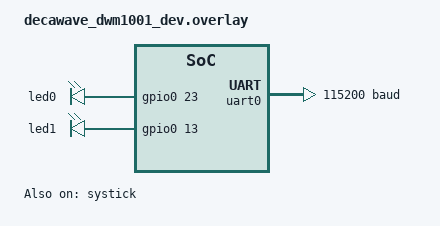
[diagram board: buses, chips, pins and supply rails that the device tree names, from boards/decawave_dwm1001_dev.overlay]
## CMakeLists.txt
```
cmake_minimum_required(VERSION 3.20.0)

find_package(Zephyr)
project(uwb_swarm_ranging)

target_sources(app PRIVATE
  # src/main.c
  src/nodes.c
  src/log.c
  src/utils.c
  src/debug-gpio.c
  src/history.c
  src/ranging-engine.c
  # src/rangings-slots.c
  src/time-synchronization.c
  src/testbeds/testbed_kiel.c
  src/testbeds/testbed_toulouse.c
  src/testbeds/testbed_drone.c
  src/testbeds/testbed_lille.c
  src/testbeds/testbed_trento_a.c
  src/testbeds/testbed_trento_b.c


  # apps/cir-evaluation.c
  # apps/ranging-with-imu.c
  # apps/cycle-slot-durations.c
  # apps/random-contention-access.c
  apps/fixed-contention-access.c
)
```

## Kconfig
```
config NUM_NODES
    int "Number of nodes"
    default 2

config GLOSSY_TX_FLOOD_START_NODE_ID
    int "Glossy TX flood start node ID"
    default 8

config DWT_MTM_OUTPUT_CIR
    bool "output channel impulse response"
    default n

config DWT_MTM_ON_DEVICE_PROCESSING
    bool "if n just output raw timestamps"
    default y

choice RANGING_OUTPUT_TARGET
    bool "output target interface"
    default RANGING_OUTPUT_RTT

config RANGING_OUTPUT_RTT
    bool "RANGING_OUTPUT_RTT"

config RANGING_OUTPUT_UART
    bool "RANGING_OUTPUT_UART"

endchoice

choice TESTBED
    bool "Testbed"
    default TESTBED_KIEL

config TESTBED_KIEL
    bool "TESTBED_KIEL"

config TESTBED_TOULOUSE
    bool "TESTBED_TOULOUSE"

config TESTBED_DRONE
    bool "TESTBED_DRONE"

config TESTBED_LILLE
    bool "TESTBED_LILLE"

config TESTBED_TRENTO_A
    bool "TESTBED_TRENTO_A"

config TESTBED_TRENTO_B
    bool "TESTBED_TRENTO_B"
endchoice


source "Kconfig.zephyr"
```

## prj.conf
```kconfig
CONFIG_LOG=y
CONFIG_LOG_DEFAULT_LEVEL=4
CONFIG_LOG_MODE_IMMEDIATE=y
CONFIG_LOG_PRINTK=y

#CONFIG_SCHED_SCALABLE=y

# CONFIG_NET_TC_THREAD_COOPERATIVE=y
CONFIG_NETWORKING=y
CONFIG_IEEE802154=y
CONFIG_IEEE802154_DW1000=y
CONFIG_NET_PKT_TIMESTAMP=y
CONFIG_IEEE802154_RAW_MODE=y
CONFIG_NEWLIB_LIBC=y
CONFIG_NEWLIB_LIBC_NANO=n

# CONFIG_NEWLIB_LIBC_FLOAT_PRINTF=y
CONFIG_CBPRINTF_FP_SUPPORT=y.

CONFIG_SERIAL=y

CONFIG_UART_ASYNC_API=y

# UART LOGGING: enable both again if log should be output through uart, not only RTT

# OPTION 1 LOG through RTT
CONFIG_UART_CONSOLE=n
CONFIG_LOG_BACKEND_UART=n
CONFIG_USE_SEGGER_RTT=y
CONFIG_LOG_BACKEND_RTT=y

# OPTION 2 LOG through UART, needed on testbeds like fit iot-lab
# CONFIG_UART_CONSOLE=y
# CONFIG_LOG_BACKEND_UART=y

CONFIG_LOG_BACKEND_RTT_BUFFER=1
# CONFIG_LOG_BACKEND_RTT_BUFFER_SIZE=4096
 # pretty much only needed if we want to output gigantic amounts of bytes for the CIR over RTT
CONFIG_LOG_BACKEND_RTT_BUFFER_SIZE=6000
# CONFIG_LOG_BACKEND_RTT_MODE_DROP=y
CONFIG_LOG_BACKEND_RTT_MODE_BLOCK=y

CONFIG_CMSIS_DSP=y
#CONFIG_CMSIS_DSP_MATRIX=y
CONFIG_CMSIS_DSP_MATRIXCHECK=y

CONFIG_HWINFO=y
CONFIG_PM_DEVICE=y
CONFIG_PM_DEVICE_RUNTIME=y
CONFIG_SYS_CLOCK_TICKS_PER_SEC=32768
# CONFIG_SYS_CLOCK_HW_CYCLES_PER_SEC=1000000

# This disables all debug logs, 2 disables all info ones as well
CONFIG_LOG_MAX_LEVEL=2

CONFIG_MAIN_STACK_SIZE=4096
CONFIG_BASE64=y

# CONFIG_MAIN_THREAD_PRIORITY=-1
CONFIG_SPI=y
CONFIG_I2C=y
CONFIG_SENSOR=y
CONFIG_NRFX_SPI2=y
CONFIG_LIS2DH=y

CONFIG_NUM_NODES=5
CONFIG_TESTBED_KIEL=y
CONFIG_GLOSSY_TX_FLOOD_START_NODE_ID=0

# CONFIG_NUM_NODES=42
# CONFIG_TESTBED_TOULOUSE=y
# CONFIG_GLOSSY_TX_FLOOD_START_NODE_ID=17

# CONFIG_NUM_NODES=14
# CONFIG_TESTBED_LILLE=y

# CONFIG_NUM_NODES=4
# CONFIG_TESTBED_DRONE=y
# CONFIG_GLOSSY_TX_FLOOD_START_NODE_ID=1

CONFIG_IEEE802154_DW1000_OTP_ANTENNA_DELAY=y

# see dts overlay, we want to use RTC for our system clock
CONFIG_CORTEX_M_SYSTICK=n
# CONFIG_SPEED_OPTIMIZATIONS=y

CONFIG_SYS_HASH_FUNC32_MURMUR3=y
CONFIG_SYS_HASH_FUNC32=y

# warning this is a memory hog, also increases the slot size to high milli seconds
CONFIG_DWT_MTM_OUTPUT_CIR=n
CONFIG_DWT_MTM_ON_DEVICE_PROCESSING=n

CONFIG_RANGING_OUTPUT_RTT=y
```

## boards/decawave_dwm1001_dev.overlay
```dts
/ {

    leds {
        compatible = "gpio-leds";
        led0: led_0 {
            gpios = <&gpio0 23 GPIO_ACTIVE_HIGH>;
        };
                led1: led_1 {
            gpios = <&gpio0 13 GPIO_ACTIVE_HIGH>;
        };
    };


    aliases {
        deb0       = &led0;
        deb1       = &led1;
    };
};

&uart0 {
	status = "okay";
	compatible = "nordic,nrf-uarte";
	//current-speed = <1000000>;
	//current-speed = <230400>;

        // the baud rates above do not seem to be running stable when using the onboard jlink of the dwm1001
	current-speed = <115200>;
	//current-speed = <57600>;
	pinctrl-0 = <&uart0_default>;
	pinctrl-1 = <&uart0_sleep>;
	pinctrl-names = "default", "sleep";
};


&systick {
 	/* Use RTC for system clock, instead of SysTick. */
 	status = "okay";
};
```

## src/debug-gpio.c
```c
#include "debug-gpio.h"

#define DEB0_NODE DT_ALIAS(deb0)
#define DEB1_NODE DT_ALIAS(deb1)

const struct gpio_dt_spec deb0 = GPIO_DT_SPEC_GET(DEB0_NODE, gpios);;
const struct gpio_dt_spec deb1 = GPIO_DT_SPEC_GET(DEB1_NODE, gpios);;

void setup_debug_gpios() {
	gpio_pin_configure_dt(&deb0, GPIO_OUTPUT | GPIO_OUTPUT_ACTIVE);
	gpio_pin_configure_dt(&deb1, GPIO_OUTPUT | GPIO_OUTPUT_ACTIVE);
}
```

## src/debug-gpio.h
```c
#ifndef DEBUG_GPIO_H
#define DEBUG_GPIO_H


extern const struct gpio_dt_spec deb0;
extern const struct gpio_dt_spec deb1;

void setup_debug_gpios();

#define USE_GPIO_DEBUG 1
#if USE_GPIO_DEBUG

#include <zephyr/drivers/gpio.h>
#include <zephyr/drivers/pinctrl.h>
#include <zephyr/drivers/uart.h>

#define TOGGLE_DEBUG_GPIO(GPIO) do { \
    gpio_pin_toggle_dt(&deb##GPIO); \
} while(0)

#define SET_GPIO_HIGH(GPIO) do { \
		gpio_pin_set_dt(&deb##GPIO, 1);	\
} while(0)

#define SET_GPIO_LOW(GPIO) do { \
		gpio_pin_set_dt(&deb##GPIO, 0);	\
} while(0)
#else
#define TOGGLE_DEBUG_GPIO(GPIO)
#define TOGGLE_DEBUG_GPIOS()
#endif

#endif
```

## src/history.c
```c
#include <zephyr/logging/log.h>
#include <zephyr/kernel.h>

#include <zephyr/net/net_core.h>
#include <zephyr/net/ieee802154_radio.h>
#include <zephyr/drivers/ieee802154/dw1000.h>
#include <stdio.h>

#include "history.h"
#include "log.h"

#define HISTORY_LENGTH 1420

K_SEM_DEFINE(hist_buf_sem, 1, 1);

struct __attribute__((__packed__)) history_record {
    uint8_t txrx_number; // of rx_number == own_number it was a tx!
    uint8_t own_number;
    int8_t rssi;
    int8_t bias_correction;
    uint16_t txrx_round;
    uint16_t txrx_slot;
    uint64_t txrx_ts;
    uint64_t bias_corrected_rx_ts;
    int32_t carrierintegrator;
    //uint8_t rx_ttcko_rc_phase;
};

static int num_stored = 0;

static struct history_record history[HISTORY_LENGTH] = {0};

void history_reset() {
    k_sem_take(&hist_buf_sem, K_FOREVER);
    memset(&history, 0, sizeof(history));
    num_stored = 0;
    k_sem_give(&hist_buf_sem);
}

size_t history_count() {
    return num_stored;
}

int history_save_rx(uint8_t own_number, uint8_t rx_number, uint16_t rx_round, uint16_t rx_slot, uint64_t rx_ts, int32_t carrierintegrator, int8_t rssi, int8_t bias_correction, uint64_t bias_corrected_rx_ts, uint8_t rx_ttcko_rc_phase) {
    k_sem_take(&hist_buf_sem, K_FOREVER);

    if (num_stored == HISTORY_LENGTH){
        k_sem_give(&hist_buf_sem);
        return -1;
    }

    struct history_record *h = &history[num_stored];

    h->txrx_number = rx_number; // of rx_number == own_number it was a tx!
    h->own_number = own_number;
    h->rssi = rssi;
    h->bias_correction = bias_correction;
    h->txrx_round = rx_round;
    h->txrx_slot = rx_slot;
    h->txrx_ts = rx_ts;
    h->bias_corrected_rx_ts = bias_corrected_rx_ts;
    h->carrierintegrator = carrierintegrator;
    //h->rx_ttcko_rc_phase = rx_ttcko_rc_phase;

    num_stored++;

    k_sem_give(&hist_buf_sem);
    return 0;
}

int history_save_tx(uint8_t own_number, uint16_t tx_round, uint16_t tx_slot, uint64_t tx_ts) {
    k_sem_take(&hist_buf_sem, K_FOREVER);

    if (num_stored == HISTORY_LENGTH){
        k_sem_give(&hist_buf_sem);
        return -1;
    }

    struct history_record *h = &history[num_stored];

    h->txrx_number = own_number; // of rx_number == own_number it was a tx!
    h->own_number = own_number;
    h->txrx_round = tx_round;
    h->txrx_slot = tx_slot;
    h->txrx_ts = tx_ts;
    h->rssi = 0;
    h->bias_correction = 0;
    h->bias_corrected_rx_ts = 0;
    h->carrierintegrator = 0;
    //h->rx_ttcko_rc_phase = 0;

    num_stored++;

    k_sem_give(&hist_buf_sem);
    return 0;
}


void history_print() {

    k_sem_take(&hist_buf_sem, K_FOREVER);

    char buf[768];
    for (size_t i = 0; i < num_stored; i++) {

        struct history_record *h = &history[i];

        if (h->own_number != h->txrx_number) {
            //snprintf(buf, sizeof(buf), "{\"event\": \"rx\", \"own_number\": %hhu, \"rx_number\": %hhu, \"rx_round\": %hu, \"rx_slot\": %hu, \"rx_ts\": %llu, \"ci\": %d, \"rssi\": %hhd, \"bias_correction\": %hhd, \"bias_corrected_rx_ts\": %llu, \"rx_ttcko_rc_phase\": %hhu}\n", h->own_number, h->txrx_number, h->txrx_round, h->txrx_slot, h->txrx_ts, h->carrierintegrator, h->rssi, h->bias_correction, h->bias_corrected_rx_ts, h->rx_ttcko_rc_phase);
            snprintf(buf, sizeof(buf), "{\"event\": \"rx\", \"own_number\": %hhu, \"rx_number\": %hhu, \"rx_round\": %hu, \"rx_slot\": %hu, \"rx_ts\": %llu, \"ci\": %d, \"rssi\": %hhd, \"bias_correction\": %hhd, \"bias_corrected_rx_ts\": %llu}\n", h->own_number, h->txrx_number, h->txrx_round, h->txrx_slot, h->txrx_ts, h->carrierintegrator, h->rssi, h->bias_correction, h->bias_corrected_rx_ts);
        } else {
            // this is a transmission.
            snprintf(buf, sizeof(buf), "{\"event\": \"tx\", \"own_number\": %hhu, \"tx_round\": %hu, \"tx_slot\": %hu, \"tx_ts\": %llu}\n", h->own_number, h->txrx_round, h->txrx_slot, h->txrx_ts);
        }
        uart_out(buf);
    }
    k_sem_give(&hist_buf_sem);
}
```

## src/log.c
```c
#include <zephyr/drivers/uart.h>
#include <zephyr/kernel.h>
#include <zephyr/logging/log.h>
#include "log.h"
#include "nodes.h"

#define LOG_BUF_SIZE (2048)

LOG_MODULE_REGISTER(logging);

#if LOG_FLUSH_DIRECTLY
#define log_out uart_out
#else
#define log_out log_out
#endif

static char serial_buf[1024]; // when TDOA is used has to be quite large, we pretty much use here most spare memory we have left over. Could off course easily be optimized

#define UART0_NODE DT_NODELABEL(uart0)
static const struct device *const uart_dev = DEVICE_DT_GET(UART0_NODE);

static const struct device* uart_device = DEVICE_DT_GET(DT_CHOSEN(zephyr_console));

K_SEM_DEFINE(log_buf_sem, 1, 1);

void uart_out(char* msg) {
    k_sem_take(&log_buf_sem, K_FOREVER);
    while (*msg != '\0') {
        uart_poll_out(uart_device, *msg);
        msg++;
    }
    k_sem_give(&log_buf_sem);
}

void uart_disabled(char* msg) {
    //NOOP
}


static char log_buf[LOG_BUF_SIZE] = {0};
static size_t log_buf_count = 0;


void log_out(char* msg) {
    k_sem_take(&log_buf_sem, K_FOREVER);

    while (*msg != '\0' && log_buf_count < LOG_BUF_SIZE) {
        log_buf[log_buf_count] = *msg;
        log_buf_count++;
        msg++;
    }

    k_sem_give(&log_buf_sem);

    if (log_buf_count == LOG_BUF_SIZE-1) {
        LOG_WRN("LOG IS FULL!!!");
    }
}

void log_flush() {
    k_sem_take(&log_buf_sem, K_FOREVER);

    for (size_t i = 0; i < log_buf_count; i++) {
        uart_poll_out(uart_device, log_buf[i]);
    }

    log_buf_count = 0;
    (void)memset(&log_buf, 0, sizeof(log_buf));

    k_sem_give(&log_buf_sem);
}


size_t log_get_count() {
    return log_buf_count;
}

/* static void uart_poll_serial_output_msg(char* msg) { */
/*     while (*msg != '\0') { */
/*         uart_poll_out(uart_dev, *msg); */
/*         msg++; */
/*     } */
/* } */

/* void uart_finished_callback(const struct device *dev, struct uart_event *evt, void *user_data) */
/* { */
/*     if(evt->type == UART_TX_DONE) { */
/*         /\* LOG_WRN("UART TX done"); *\/ */
/*     } else if(evt->type == UART_TX_ABORTED) { */
/*         LOG_WRN("UART TX aborted"); */
/*     } */

/*     k_sem_give(&uart_transfer_finished); */
/* } */

/* void output_measurements_uart(const struct measurement *g_measurements, */
/*     int tof_count, uint64_t rtc_slot_ts) { */
/*     int written = 0; */
/*     uint8_t insert_comma; */

/*     // Create output */
/*     written += snprintf(serial_buf, sizeof(serial_buf), "{\"event\":\"twr\",\"i\":%u,\"rtc_round_ts\": %llu,\"t\":[", */
/*         node_ranging_id, rtc_slot_ts); */

/*     insert_comma = 0; */
/*     for (int i = 0; i < tof_count; i++) { */
/*         if(g_measurements[i].ranging_initiator_id == node_ranging_id) { */
/*             uint8_t id = g_measurements[i].ranging_responder_id; */
/*             float dist = time_to_dist(g_measurements[i].tof) * DIST_OUTPUT_UNIT; */

/*             if (insert_comma) { */
/*                 written += snprintf(serial_buf + written, sizeof(serial_buf) - written, ","); */
/*             } */

/*             written += snprintf(serial_buf + written, sizeof(serial_buf) - written, */
/*                 "{\"i\":%u,\"d\":%d,\"q\":%d}", id, (int32_t)(dist), 100); */

/*             insert_comma = 1; */
/*         } */
/*     } */

/*     written += snprintf(serial_buf + written, sizeof(serial_buf) - written, "]}\r\n"); */

/*     uart_poll_serial_output_msg(serial_buf); */

/*     written = 0; */
/*     written += */
/*         snprintf(serial_buf, sizeof(serial_buf), */
/*             "{\"event\":\"td\",\"i\":%u,\"rtc_round_ts\": %llu,\"t\":[", node_ranging_id, rtc_slot_ts); */
/*     insert_comma = 0; */

/*     for (int i = 0; i < tof_count; i++) { */
/*         uint8_t initiator = g_measurements[i].ranging_responder_id, responder = g_measurements[i].ranging_initiator_id; */

/*         if(initiator != node_ranging_id && responder != node_ranging_id && g_measurements[i].tdoa != NAN) { */
/*             float dist = time_to_dist(g_measurements[i].tdoa) * DIST_OUTPUT_UNIT; */

/*             if (insert_comma) { */
/*                 written += snprintf(serial_buf + written, sizeof(serial_buf) - written, ","); */
/*             } */

/*             written += */
/*                 snprintf(serial_buf + written, sizeof(serial_buf) - written, */
/*                     "{\"i\":[%u,%u],\"d\":%d,\"q\":%d}", */
/*                     initiator, responder, (int32_t)(dist), 100); */
/*             insert_comma = 1; */
/*         } */
/*     } */

/*     written += snprintf(serial_buf + written, sizeof(serial_buf) - written, "]}\r\n"); */

/*     uart_poll_serial_output_msg(serial_buf); */
/* } */

#if CONFIG_DWT_MTM_ON_DEVICE_PROCESSING
void output_measurements_rtt(const struct measurement *g_measurements,
    int tof_count, uint64_t rtc_slot_ts, const char *type) {
    uint8_t insert_comma;

    printk("{\"event\":\"twr\", \"type\": \"%s\", \"i\":%u,\"rtc_round_ts\": %llu,\"t\":[",
        type, node_ranging_id, rtc_slot_ts);

    insert_comma = 0;
    for (int i = 0; i < tof_count; i++) {
        if(g_measurements[i].ranging_initiator_id == node_ranging_id) {
            uint8_t id = g_measurements[i].ranging_responder_id;
            float dist = time_to_dist(g_measurements[i].tof) * DIST_OUTPUT_UNIT;

            if (insert_comma) {
                printk(",");
            }

            printk("{\"i\":%u,\"d\":%d,\"q\":%d}", id, (int32_t)(dist), 100);

            insert_comma = 1;
        }
    }
    printk("]}\r\n");

    printk("{\"event\":\"td\", \"type\": \"%s\",\"i\":%u,\"rtc_round_ts\": %llu,\"t\":[", type, node_ranging_id, rtc_slot_ts);
    insert_comma = 0;

    for (int i = 0; i < tof_count; i++) {
        uint8_t initiator = g_measurements[i].ranging_responder_id, responder = g_measurements[i].ranging_initiator_id;

        if(initiator != node_ranging_id && responder != node_ranging_id && g_measurements[i].tdoa != NAN) {
            float dist = time_to_dist(g_measurements[i].tdoa) * DIST_OUTPUT_UNIT;

            if (insert_comma) {
                printk(",");
            }

            printk("{\"i\":[%u,%u],\"d\":%d,\"q\":%d}", initiator, responder, (int32_t)(dist), 100);
            insert_comma = 1;
        }
    }
    printk("]}\r\n");
}
#endif

void output_frame_timestamps(const struct dwt_ranging_frame_info *frame_infos,
    const struct mtm_ranging_config *conf, uint64_t rtc_slot_ts, const char *additional)
{
    for (int i = 0; i < conf->phases-1; i++) { // the last phase/phase is not of importance for us
        for(int j = 0; j < conf->slots_per_phase; j++) {
            const struct dwt_ranging_frame_info *curr_frame_info = &frame_infos[i*conf->slots_per_phase + j];

	    if (curr_frame_info->frame != NULL) {
                const struct dwt_ranging_frame_buffer *curr_frame = curr_frame_info->frame;

		if (curr_frame_info->type == DWT_RANGING_TRANSMITTED_FRAME) {
		    printk("{\"event\": \"tx\", \"own_id\": %u, \"rtc_round_ts\": %llu, \"phase\": "
			   "%u, \"slot\": %u, \"ts\": %llu",
                        conf->ranging_id, rtc_slot_ts, i, j, curr_frame_info->timestamp);
		} else {
		    printk("{\"event\": \"rx\", \"own_id\": %u, \"other_id\": %u,"
			   "\"rtc_round_ts\": %llu, \"phase\": %u, \"slot\": %u,"
			   "\"fp_ampl1\": %u, \"fp_ampl2\": %u, \"fp_ampl3\": %u, \"std_noise\": %u,"
			   "\"fp_index\": %u, \"cir_pwr\": %u, \"cfo\": %d, \"rx_pacc\": %u,"
			   "\"ts\": %llu",
			   conf->ranging_id, curr_frame->ranging_id, rtc_slot_ts, i, j,
			   curr_frame_info->fp_ampl1, curr_frame_info->fp_ampl2,
                        curr_frame_info->fp_ampl3, curr_frame_info->std_noise, curr_frame_info->fp_index >> 6,
			   curr_frame_info->cir_pwr, (int)(curr_frame_info->cfo_ppm * 1e6),
                        curr_frame_info->rx_pacc, curr_frame_info->timestamp);
		}

                if (additional != NULL) {
                    printk(", %s", additional);
                }

                printk("}\n");
            }
        }
    }
}



/* int output_cir_uart(int slot, int phase, const uint8_t *cir_memory, size_t size) */
/* { */

/*     // for debug purposes we will measure the timing this takes, which should be quite hefty */
/*     unsigned int start_ts = k_cycle_get_32(), end_ts; */

/*     int cir_bytes_written = 0; */
/*     int ret, length; */
/*     uart_callback_set(uart_dev, uart_finished_callback, NULL); */

/*     k_sem_take(&uart_transfer_finished, K_FOREVER); */
/*     length = snprintf(serial_buf, sizeof(serial_buf), */
/* 				       "{\"event\": \"cir\", \"rtc\": %llu, \"slot\": %d, " */
/* 				       "\"phase\": %d, \"length\": %d, \"data\":\"", */
/* 				       next_event_time, slot, phase, size); */

/*     ret = uart_tx(uart_dev, serial_buf, length, SYS_FOREVER_US); */

/*     if (ret) { */
/*         LOG_WRN("UART TX failed: %d", ret); */
/* 	k_sem_give(&uart_transfer_finished); */

/*         return -1; */
/*     } */

/*     // Base64 encode the data */
/*     do { */
/*         k_sem_take(&uart_transfer_finished, K_FOREVER); // always wait for previous uart transfer to finish */

/* 	ret = base64_encode(serial_buf, sizeof(serial_buf), &length, */
/* 				 cir_memory + cir_bytes_written, */
/* 				 MIN(CIR_CHUNK_WRITE_SIZE, size - cir_bytes_written)); */

/* 	if (ret >= 0) { */
/* 	    ret = uart_tx(uart_dev, serial_buf, length, SYS_FOREVER_US); */

/*             if (ret) { */
/*                 LOG_ERR("UART TX failed: %d", ret); */
/*                 k_sem_give(&uart_transfer_finished); */
/* 	    } */

/*             cir_bytes_written += CIR_CHUNK_WRITE_SIZE; */
/* 	} else { */
/* 	    LOG_ERR("Base64 encoding failed"); */
/*             k_sem_give(&uart_transfer_finished); */
/*             return -1; */
/*         } */
/*     } while ((int)size - cir_bytes_written > 0); */

/*     // wait for encoded part to finish */
/*     k_sem_take(&uart_transfer_finished, K_FOREVER); */

/*     length = snprintf(serial_buf, sizeof(serial_buf), "\"}\n"); */
/*     ret = uart_tx(uart_dev, serial_buf, length, SYS_FOREVER_US); */

/*     if (ret) { */
/*         LOG_ERR("UART TX failed: %d", ret); */
/*         k_sem_give(&uart_transfer_finished); */
/*     } */

/*     end_ts = k_cycle_get_32(); */

/*     // sys_clock_hw_cycles_per_sec() */
/*     LOG_WRN("CIR output took %d ms", ( (end_ts - start_ts) * 1000 ) / sys_clock_hw_cycles_per_sec()); */

/*     return 0; */
/* } */
```

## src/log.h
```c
#ifndef LOG_H
#define LOG_H

#include <stdint.h>
#include <zephyr/drivers/ieee802154/dw1000.h>

void uart_out(char* msg);
void uart_disabled(char *msg);
void output_measurements_rtt(const struct measurement *g_measurements, int tof_count,
			     uint64_t rtc_slot_ts, const char *type);
void output_frame_timestamps(const struct dwt_ranging_frame_info *frame_infos,
    const struct mtm_ranging_config *conf, uint64_t rtc_slot_ts, const char *additional);

void log_out(char* msg);
void log_flush();
#endif
```

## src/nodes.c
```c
#include <zephyr/kernel.h>
#include <zephyr/drivers/hwinfo.h>
#include "nodes.h"

// testbed defined in testbed.c

inline size_t pair_index(uint16_t a, uint16_t b) {
       return PAIR_INDEX(a,b);
}


uint16_t get_own_node_id() {
    uint8_t id_buf[2] = {0};
    ssize_t copied_bytes = hwinfo_get_device_id(id_buf, sizeof(id_buf));
    return id_buf[0] << 8 | id_buf[1];
}

int8_t get_node_number(uint16_t node_id) {
    for (int i = 0; i < NUM_NODES; i++) {
        if (node_id == node_ids[i]) {
            return i;
        }
    }

    return -1;  //node number not found!
}
```

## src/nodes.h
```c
#ifndef NODE_NUMBERS_H
#define NODE_NUMBERS_H

#include <arm_math_f16.h>
#include <zephyr/logging/log.h>
#include <stdio.h>

#define NUM_NODES CONFIG_NUM_NODES

#define PAIRS(X) (((X)*((X)-1))/2)
#define NUM_PAIRS (PAIRS(NUM_NODES))
#define PAIR_INDEX(A,B) (((MIN(A,B)*(MIN(A,B)-1))/2+MAX(A,B)))


extern int16_t node_factory_antenna_delay_offsets[NUM_NODES];
extern uint16_t node_ids[NUM_NODES];
extern uint16_t neighbor_graph_degree[NUM_NODES];
extern float32_t node_distances[NUM_PAIRS];
extern uint16_t aloha_access_prob[NUM_NODES];

#define ALOHA_ACCESS_PROB_MULTIPLIER 1000


size_t pair_index(uint16_t a, uint16_t b);
uint16_t get_own_node_id();
int8_t get_node_number(uint16_t node_id);
int8_t get_range_bias_by_rssi(int8_t rssi);


#endif
```

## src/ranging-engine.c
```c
#include "ranging-engine.h"

#if CONFIG_DWT_MTM_ON_DEVICE_PROCESSING
static uint8_t g_ranging_ids[MAX_ROUND_LENGTH];
static struct freq_offset g_offsets[2*MAX_ROUND_LENGTH*MAX_ROUND_LENGTH]; // in the worst case we will get a quadratic amount of g_measurements + for each node pair a passively extracted frequency offset
static struct measurement g_measurements[MAX_ROUND_LENGTH * MAX_ROUND_LENGTH];
static struct twr_template g_templates[MAX_ROUND_LENGTH * MAX_ROUND_LENGTH];

static inline uint64_t correct_overflow(uint64_t end_ts, uint64_t start_ts) {
    if (end_ts < start_ts) {
        end_ts += 0xFFFFFFFFFF;
    }

    return end_ts - start_ts;
}

int valid_fp_index_p(uint16_t fp_index) {
    int32_t diff = (int32_t) 750 - ((int32_t) fp_index >> 6);
    return ( diff <  FP_INDEX_VALIDY_RANGE )
        && ( diff > -FP_INDEX_VALIDY_RANGE );
}

int32_t
compute_prop_time(int32_t initiator_roundtrip, int32_t initiator_reply,
    int32_t replier_roundtrip, int32_t replier_reply) {

    return (int32_t)(( ((int64_t) initiator_roundtrip * replier_roundtrip)
            - ((int64_t) initiator_reply * replier_reply))
        /
        ((int64_t) initiator_roundtrip
            +  replier_roundtrip
            +  initiator_reply
            +  replier_reply));
}


float time_to_dist(float tof) {
    return (float)tof * SPEED_OF_LIGHT_M_PER_UWB_TU;
}

float calculate_propagation_time_alternative(uint64_t tx_init, uint64_t rx_init, uint64_t tx_resp,
					     uint64_t rx_resp, uint64_t tx_final, uint64_t rx_final)
{
    static float relative_drift_offset;
    static int64_t responder_duration, initiator_duration;
    static int64_t round_duration_a, delay_duration_b;
    /* static float drift_offset_int, two_tof_int; */
    static int64_t drift_offset_int, two_tof_int;

    initiator_duration   = correct_overflow(tx_final, tx_init);
    responder_duration = correct_overflow(rx_final, rx_init);

    // factor determining whether B's clock runs faster or slower measured from the perspective of our clock
    // a positive factor here means that the clock runs faster than ours
    /* relative_drift_offset = (float)((int64_t)initiator_duration-(int64_t)responder_duration) / (float)(responder_duration); */
    relative_drift_offset = (float)((int64_t)initiator_duration-(int64_t)responder_duration) / (float)(responder_duration);


    round_duration_a = correct_overflow(rx_resp, tx_init);
    delay_duration_b = correct_overflow(tx_resp, rx_init);

    /* drift_offset_int = -relative_drift_offset * (float) delay_duration_b; */
    drift_offset_int = round(-relative_drift_offset * (float) delay_duration_b);

    /* two_tof_int = (float)round_duration_a - (float)delay_duration_b + drift_offset_int; */
    two_tof_int = (int64_t)round_duration_a - (int64_t)delay_duration_b + drift_offset_int;

    return ((float) two_tof_int) * 0.5;
}

/* Assumptions: A node may not change its position in the ranging round in subsequent phases, i.e.,
   if it transmitted in slot N in round K it should also transmit in slot N in round K+1.

   returns amount of calculated twr distances for given initiatior id.
 */
int fill_twr_template_from_frames(const struct dwt_ranging_frame_info *frame_infos,
    uint8_t initiator_id, int round_length,
    int phases, struct twr_template *twr_templates,
    int with_reject
    )
{
    int responder_count = 0;
    uint64_t tx_init = UINT64_MAX, tx_final = UINT64_MAX;

    // these we will reference more often
    const struct dwt_ranging_frame_buffer *initiator_phase_1_frame = NULL, *initiator_phase_2_frame = NULL;
    uint8_t initiation_node_slot_offset = UINT8_MAX;

    if (round_length <= 1) {
	LOG_ERR("Invalid round length");
        return -EINVAL;
    }

    // first sweep find the initiation frame and finalization frame of the initiating node
    for(int i = round_length; i < phases*round_length; i++) {
        const struct dwt_ranging_frame_info *frame_info = &frame_infos[i];

        if(frame_info->frame != NULL) {
            const struct dwt_ranging_frame_buffer *frame = frame_info->frame;

            if(frame->ranging_id == initiator_id) {
                if(!initiator_phase_1_frame) {
                    initiator_phase_1_frame = frame;
                    initiation_node_slot_offset = i - round_length;

                    // grab tx_init from buffer
		    tx_init = from_packed_dwt_ts(initiator_phase_1_frame->tx_ts);
                } else {
                    initiator_phase_2_frame = frame;
                    // grab tx_final from buffer
		    tx_final = from_packed_dwt_ts(initiator_phase_2_frame->tx_ts);
                    break;
                }
            }
        }
    }

    // swipe once through frames to capture all ranging ids and associate them with a position in distances
    for(int i = 0; i < round_length; i++) {
        const struct dwt_ranging_frame_info *frame_info = &frame_infos[i];

        if(frame_info->frame != NULL) {
            const struct dwt_ranging_frame_buffer *frame = frame_info->frame;

            if(frame->ranging_id != initiator_id) {
                twr_templates[responder_count].ranging_initiator_id = initiator_id;
                twr_templates[responder_count].ranging_responder_id =
                    frame->ranging_id;

                // init values to UINT64_MAX
                twr_templates[responder_count].tx_init = tx_init;
                twr_templates[responder_count].tx_final = tx_final;

                twr_templates[responder_count].rx_init = UINT64_MAX;
                twr_templates[responder_count].tx_resp = UINT64_MAX;
                twr_templates[responder_count].rx_resp = UINT64_MAX;
                twr_templates[responder_count].rx_final = UINT64_MAX;

                twr_templates[responder_count].local_rx_init = UINT64_MAX;
                twr_templates[responder_count].local_rx_resp = UINT64_MAX;
                twr_templates[responder_count].local_rx_final = UINT64_MAX;

                responder_count++;
            }
        }
    }

/* next we retrieve all timestamps that are specific to other nodes and are not shared */
/* between all calculations */

    // first find rx_init, tx_resp and rx_resp
    for(int i = 0; i < round_length; i++) {
        if(i != initiation_node_slot_offset) {
            uint64_t rx_init = UINT64_MAX, tx_resp = UINT64_MAX, rx_resp = UINT64_MAX, rx_final = UINT64_MAX;
            uint64_t local_rx_init = UINT64_MAX, local_rx_resp = UINT64_MAX, local_rx_final = UINT64_MAX;


            //  TODO the naming here is not good yet, the frames do not respond to the respective
            // names for the protocol frames i.e., the initiation frame is originally send in phase
            // 1, depending on the slot order the response frame might either be part of phase 1 or
            // the subsequent phase. i.e., we should probably find a better name here.
	    const struct dwt_ranging_frame_info *responder_phase_1_frame_info =
		    &frame_infos[round_length + i];
	    const struct dwt_ranging_frame_buffer *responder_phase_1_frame =
		    responder_phase_1_frame_info->frame;

	    const struct dwt_ranging_frame_info *responder_phase_2_frame_info = NULL;
	    const struct dwt_ranging_frame_buffer *responder_phase_2_frame = NULL;

	    if (responder_phase_1_frame_info->frame == NULL) {
                continue;
	    }

            if(phases > 2) {
		responder_phase_2_frame_info = &frame_infos[2 * round_length + i];
                responder_phase_2_frame = responder_phase_2_frame_info->frame;
	    }

	    uint8_t responder_id = responder_phase_1_frame->ranging_id;

	    // extract info from phase_1 frame
	    if (responder_phase_1_frame_info->frame != NULL) {
                if(with_reject && !valid_fp_index_p(responder_phase_1_frame_info->fp_index) ) {
                    continue;
		}

                // in any case the received phase_1 frame will contain rx_init
                for(int k = 0; k < responder_phase_1_frame->rx_ts_count; k++) {
                    if(responder_phase_1_frame->rx_ts[k].ranging_id == initiator_id) {
                        rx_init = from_packed_dwt_ts(responder_phase_1_frame->rx_ts[k].ts);
                        break;
                    }
		}

		if (i > initiation_node_slot_offset) {
                    tx_resp = from_packed_dwt_ts(responder_phase_1_frame->tx_ts);

                    // in our own initiation frame we will find rx_resp
                    for(int k = 0; k < initiator_phase_1_frame->rx_ts_count; k++) {
                        if(initiator_phase_1_frame->rx_ts[k].ranging_id == responder_id) {
                            rx_resp = from_packed_dwt_ts(initiator_phase_1_frame->rx_ts[k].ts);
                            break;
                        }
                    }
                }
	    }

	    if (responder_phase_2_frame_info != NULL && responder_phase_2_frame_info->frame != NULL) {
                if(with_reject && !valid_fp_index_p(responder_phase_2_frame_info->fp_index) ) {
                    continue;
		}

                // in case of contention based access this might happen
                if(responder_phase_1_frame->ranging_id != responder_phase_2_frame->ranging_id) {
                    LOG_ERR("Initiation and finalization frame do not match %u != %u", responder_phase_1_frame->ranging_id, responder_phase_2_frame->ranging_id);
                    continue;
                }

                // in any case we also find the rx_final timestamp in the received phase_2 frame
                for(int k = 0; k < responder_phase_2_frame->rx_ts_count; k++) {
                    if(responder_phase_2_frame->rx_ts[k].ranging_id == initiator_id) {
                        rx_final = from_packed_dwt_ts(responder_phase_2_frame->rx_ts[k].ts);
                        break;
                    }
		}

                if(i < initiation_node_slot_offset) {
                    tx_resp = from_packed_dwt_ts(responder_phase_2_frame->tx_ts);

                    // in our own finalization frame we will find rx_resp
                    for(int k = 0; k < initiator_phase_2_frame->rx_ts_count; k++) {
                        if(initiator_phase_2_frame->rx_ts[k].ranging_id == responder_id) {
                            rx_resp = from_packed_dwt_ts(initiator_phase_2_frame->rx_ts[k].ts);
                            break;
                        }
                    }
                }
            }

            // --- Passive extraction ---
            if(initiator_id != node_ranging_id) {
                // Find local timestamps, for this we now directly look at the frame reception
                // timestamps in the info frames (Above we found the timestamps from phase N in
                // Phase N+1) We read this directly from the info frames, since in case of a
                // fully passive receiver, we won't have any transmission frames to get retrieve
                // that data from that node
                const struct dwt_ranging_frame_info *local_init_info         = &frame_infos[initiation_node_slot_offset];
                const struct dwt_ranging_frame_info *local_response_info     = NULL;
		const struct dwt_ranging_frame_info *local_finalization_info = NULL;

		if (phases > 1) {
                    local_response_info = &frame_infos[i > initiation_node_slot_offset ? i : round_length + i];
		}

		if (phases > 2) {
                    local_finalization_info = &frame_infos[round_length + initiation_node_slot_offset];
                }

                if(local_init_info->frame != NULL && local_init_info->frame->ranging_id == initiator_id) {
                    local_rx_init = local_init_info->timestamp;
                }

                if(local_response_info->frame != NULL && local_response_info->frame->ranging_id == responder_id) {
                    local_rx_resp = local_response_info->timestamp;
                }

                if(local_finalization_info->frame != NULL && local_finalization_info->frame->ranging_id == initiator_id) {
                    local_rx_final = local_finalization_info->timestamp;
                }
            }

            // store in twr_templates
            for(int k = 0; k < responder_count; k++) {
                if(twr_templates[k].ranging_responder_id == responder_id) {
                    twr_templates[k].rx_init = rx_init;
                    twr_templates[k].tx_resp = tx_resp;
                    twr_templates[k].rx_resp = rx_resp;
                    twr_templates[k].rx_final = rx_final;

                    twr_templates[k].local_rx_init  = local_rx_init;
                    twr_templates[k].local_rx_resp  = local_rx_resp;
                    twr_templates[k].local_rx_final = local_rx_final;
                    break;
                }
            }
        }
    }

    return responder_count;
}



int have_freq_offset(struct freq_offset *offsets, int offsets_length, uint8_t from_id, uint8_t to_id) {
    for(int i = 0; i < offsets_length; i++) {
        if(offsets[i].from_id == from_id && offsets[i].to_id == to_id) {
            return 1;
        }
    }

    return 0;
}

int frequencies_from_cfos(const struct dwt_ranging_frame_info *frame_infos, int round_length,
			  int phases, struct freq_offset *offsets)
{
    int offset_cnt = 0;

    for(int i = 0; i < round_length; i++) {
        const struct dwt_ranging_frame_info *frame_info = &frame_infos[i];

        if(frame_info->frame != NULL) {
	    struct freq_offset *curr_off = &offsets[offset_cnt];

            curr_off->from_id = frame_info->frame->ranging_id;
	    curr_off->to_id = node_ranging_id;

	    if (have_freq_offset(offsets, offset_cnt, curr_off->from_id, curr_off->to_id)) {
                continue;
            }

	    curr_off->offset = -(frame_info->cfo_ppm / 1.0e6);

            offset_cnt++;
        }
    }

    return offset_cnt;
}


int extract_round_templates(const struct dwt_ranging_frame_info *frame_infos,
    const struct mtm_ranging_config *conf,
    enum extraction_mode mode)
{
    int ranging_id_count = get_ranging_ids(frame_infos, g_ranging_ids, conf->round_length);

    int extracted_templates = 0;
    if(mode == EXTRACT_LOCAL_ONLY) {
        int template_cnt = fill_twr_template_from_frames(frame_infos, node_ranging_id, conf->round_length, conf->phases, g_templates, EXTRACT_WITH_REJECT);
        extracted_templates += template_cnt;
    } else if (mode == EXTRACT_LOCAL_BIDIRECTIONAL) {
        LOG_ERR("Not implemented yet");
        return -1;
    } else {
        for(int i = 0; i < ranging_id_count; i++) {
            int template_cnt = fill_twr_template_from_frames(
                frame_infos, g_ranging_ids[i], conf->round_length, conf->phases,
                g_templates + extracted_templates, EXTRACT_WITH_REJECT);

            if (template_cnt > 0) {
                // TODO remove again
                extracted_templates += template_cnt;
            }
        }
    }

    return extracted_templates;
}

int calculate_frequency_offsets(const struct twr_template *twr_templates, int template_count, struct freq_offset *offsets) {
    int offset_cnt = 0;

    for(int i = 0; i < template_count; i++) {
        const struct twr_template *curr_tmpl = &twr_templates[i];
        struct freq_offset *curr_off = &offsets[offset_cnt];
        uint8_t initiator_id = curr_tmpl->ranging_initiator_id, responder_id = curr_tmpl->ranging_responder_id;


        if(curr_tmpl->tx_init == UINT64_MAX || curr_tmpl->rx_init == UINT64_MAX || curr_tmpl->tx_final == UINT64_MAX || curr_tmpl->rx_final == UINT64_MAX) {
            continue;
        }

        uint64_t initiator_duration = correct_overflow(curr_tmpl->tx_final,  curr_tmpl->tx_init);
        uint64_t responder_duration = correct_overflow(curr_tmpl->rx_final, curr_tmpl->rx_init);

        curr_off->from_id = responder_id;
	curr_off->to_id = initiator_id;

        if (!have_freq_offset(offsets, offset_cnt, curr_off->to_id, curr_off->from_id)) {
	    curr_off->offset = (float)((int64_t)initiator_duration - (int64_t)responder_duration) /
	        	       (float)(responder_duration);
            offset_cnt++;
        }


        // TODO maybe we can do this code somewhat cleaner, for instance i am still not sure if we
        // should do this independent of the detection of a completed twr round (for now this code
        // assumes that we only want to know the offset for the later calculation of a tdoa
        // measurement based on a overheard TWR exchange, but maybe we also have use for these
        // values independent of the existance of a successfull round?
        if(initiator_id != node_ranging_id && responder_id != node_ranging_id) {
            curr_off = &offsets[offset_cnt];

            if(curr_tmpl->local_rx_final == UINT64_MAX || curr_tmpl->local_rx_init == UINT64_MAX) {
		continue;
            }

            // we are the other in this case
            responder_duration = correct_overflow(curr_tmpl->local_rx_final, curr_tmpl->local_rx_init);

            curr_off->from_id = initiator_id;
            curr_off->to_id = node_ranging_id;

	    if (!have_freq_offset(offsets, offset_cnt, curr_off->to_id, curr_off->from_id)) {
                curr_off->offset = (float)((int64_t)responder_duration - (int64_t)initiator_duration) /
                    (float)(initiator_duration);
                offset_cnt++;
            }
        }
    }

    return offset_cnt;
}

/* calculate twr and tdoa estimataes from extracted templates.  In case that offsets is null do not
   compensate for frequency deviation
*/
int calculate_measurements(
    const struct twr_template *twr_templates,
    int template_count,
    const struct freq_offset *offsets,
    int frequency_count,
    struct measurement *measurements) {
    int meas_cnt = 0;

    // iterate over all g_templates
    for (int i = 0; i < template_count; i++) {
	const struct twr_template *curr_tmpl = &twr_templates[i];

	if (curr_tmpl->tx_init == UINT64_MAX || curr_tmpl->rx_init == UINT64_MAX ||
	    curr_tmpl->tx_resp == UINT64_MAX || curr_tmpl->rx_resp == UINT64_MAX) {
	    continue;
        }

        uint64_t round_dur_initiator =
            correct_overflow(curr_tmpl->rx_resp, curr_tmpl->tx_init);
        uint64_t delay_dur_responder =
            correct_overflow(curr_tmpl->tx_resp,  curr_tmpl->rx_init);
	int64_t drift_offset_int = 0;

        if(offsets != NULL) {
            const struct freq_offset *responder_offset_to_initiator = NULL;
            for (int j = 0; j < frequency_count; j++) {
		if (offsets[j].from_id == curr_tmpl->ranging_responder_id &&
		    offsets[j].to_id == curr_tmpl->ranging_initiator_id) {
                    responder_offset_to_initiator = &offsets[j];
                    break;
                }
            }

            if (responder_offset_to_initiator != NULL) {
                drift_offset_int = round(-responder_offset_to_initiator->offset * (float)delay_dur_responder);
            }
	}

        measurements[meas_cnt].ranging_initiator_id = curr_tmpl->ranging_initiator_id;
        measurements[meas_cnt].ranging_responder_id = curr_tmpl->ranging_responder_id;
        measurements[meas_cnt].tof = (float)((int64_t)round_dur_initiator - (int64_t)delay_dur_responder + drift_offset_int) * 0.5;
	measurements[meas_cnt].tdoa = NAN;

        // calculate passive tdoa value
	if (curr_tmpl->ranging_initiator_id != node_ranging_id &&
	    curr_tmpl->ranging_responder_id != node_ranging_id) {

            if (curr_tmpl->local_rx_init == UINT64_MAX || curr_tmpl->local_rx_resp == UINT64_MAX) {
                continue;
	    }

	    uint64_t tx_reception_diff =
		    correct_overflow(curr_tmpl->local_rx_resp, curr_tmpl->local_rx_init);
	    int64_t passive_to_initiator_drift_offset_int = 0;

	    if (offsets != NULL) {
		const struct freq_offset *passive_offset_to_initiator = NULL;
		const struct freq_offset *passive_offset_to_responder = NULL;

                for (int j = 0; j < frequency_count; j++) {
		    if (offsets[j].from_id == curr_tmpl->ranging_initiator_id &&
			offsets[j].to_id == node_ranging_id) {
                        passive_offset_to_initiator = &offsets[j];
                        break;
                    }
		}

                for (int j = 0; j < frequency_count; j++) {
		    if (offsets[j].from_id == curr_tmpl->ranging_responder_id &&
			offsets[j].to_id == node_ranging_id) {
                        passive_offset_to_responder = &offsets[j];
                        break;
                    }
		}

                if(passive_offset_to_initiator == NULL || passive_offset_to_responder == NULL) {
		    continue;
                }

		passive_to_initiator_drift_offset_int =
			round(passive_offset_to_initiator->offset * (float)round_dur_initiator +
			      passive_offset_to_responder->offset * (float)delay_dur_responder);
	    }

            measurements[meas_cnt].tdoa =
                ((float)((int64_t)round_dur_initiator + (int64_t)delay_dur_responder +
                    passive_to_initiator_drift_offset_int -
                    (int64_t)(2 * tx_reception_diff))) * 0.5;

	    /* measurements[meas_cnt].tdoa = (int64_t)round_dur_initiator - */
	    /*     			  measurements[meas_cnt].tof - tx_reception_diff + */
	    /*     			  passive_to_initiator_drift_offset_int; */
        }

        meas_cnt++;
    }

    return meas_cnt;
}
#endif
```

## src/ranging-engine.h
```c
#ifndef RANGING_ENGINE_H
#define RANGING_ENGINE_H

#include <stdint.h>
#include <zephyr/drivers/ieee802154/dw1000.h>

enum extraction_mode {
  EXTRACT_LOCAL_ONLY,
  EXTRACT_LOCAL_BIDIRECTIONAL,
  EXTRACT_ALL
};

/* all these data structures are expected to be only be relevant for the duration of a ranging round
 * therefore the additional space we have to spent for associating each item with the pair of nodes
 * is assumed to be negligible.
 */
struct twr_template
{
    uint8_t ranging_initiator_id, ranging_responder_id;
    uint64_t tx_init, rx_init, tx_resp, rx_resp, tx_final, rx_final;

    // these are only relevant if ranging_initiator_id and ranging_responder_id are both not our own ranging id
    uint64_t local_rx_init, local_rx_resp, local_rx_final;
};

struct freq_offset
{
    uint8_t from_id, to_id;
    float offset;
};

struct measurement
{
    uint8_t ranging_initiator_id, ranging_responder_id;
    float tof, tdoa;
    float quality; // currently unused but useful in the future
};

int32_t compute_prop_time(int32_t initiator_roundtrip, int32_t initiator_reply,
			  int32_t replier_roundtrip, int32_t replier_reply);
float time_to_dist(float tof);
float calculate_propagation_time_alternative(uint64_t tx_init, uint64_t rx_init, uint64_t tx_resp,
					     uint64_t rx_resp, uint64_t tx_final,
					     uint64_t rx_final);

int fill_twr_template_from_frames(const struct dwt_ranging_frame_info *frame_infos,
				  uint8_t initiator_id, int round_length, int phases,
				  struct twr_template *twr_templates, int with_reject);

int have_freq_offset(struct freq_offset *offsets, int offsets_length, uint8_t from_id,
		     uint8_t to_id);

int frequencies_from_cfos(const struct dwt_ranging_frame_info *frame_infos, int round_length,
			  int phases, struct freq_offset *offsets);

int extract_round_templates(const struct dwt_ranging_frame_info *frame_infos,
			    const struct mtm_ranging_config *conf, enum extraction_mode mode);

int calculate_measurements(const struct twr_template *twr_templates, int template_count,
			   const struct freq_offset *offsets, int frequency_count,
			   struct measurement *measurements);

int calculate_frequency_offsets(const struct twr_template *twr_templates, int template_count,
				struct freq_offset *offsets);


#endif
```

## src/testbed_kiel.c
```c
#include "nodes.h"
// ----------------------
// Definition of Testbed lille

#if CONFIG_TESTBED_KIEL

#if NUM_NODES>13
#error Testbed Kiel only has 12 nodes
#elif NUM_NODES<13
#warning Testbed Kiel has more nodes available (12 in total)
#endif

uint16_t node_ids[NUM_NODES] = {
        0x4b51, // gateway-stativ-2-dwm1001-000760118589
        0xc7f6, // gateway-stativ-1-dwm1001-000760120221
        0x4d0f, // gateway-stativ-3-dwm1001-000760119517
	0x2b75, // profiled-gateway-2-dwm1001-000760119483
	0x0320, // profiled-gateway-1
	0xe680, // gateway-503-1-dwm1001-000760120328
	0x9d21, // mobile-gateway
	0xf39f, // gateway-503-0-dwm1001-000760120293
	0xc503, // gateway-503-2-dwm1001-000760120263
	0xa96b, // gateway-503-6-dwm1001-000760120318
	0xbdea, // gateway-503-9-dwm1001-000760120369
	0xde5d, // gateway-503-9-dwm1001-000760120245 Note: bad OTP values
	0x5321, // gateway-503-8-dwm1001-000760120244
};



uint16_t neighbor_graph_degree[NUM_NODES] = {0x00};

uint16_t aloha_access_prob[NUM_NODES] = {
	800,
	800,
	800,
	800,
	800,
	800,
	800,
	800,
	800,
	800,
	800,
	800,
	800
};

int16_t node_factory_antenna_delay_offsets[NUM_NODES] = {
    0x00
};


float32_t node_distances[NUM_PAIRS] = {
    0x00
};

#endif
```

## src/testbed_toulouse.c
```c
#include "nodes.h"
// ----------------------
// Definition of Testbed lille

#if CONFIG_TESTBED_TOULOUSE

#if NUM_NODES>42
#error Testbed toulouse only has 42 nodes
#elif NUM_NODES<42
#warning Testbed toulouse has more nodes available (42 in total)
#endif

uint16_t node_ids[NUM_NODES] = {
	0x42ac, // dwm1001-35,
	0x6a65, // dwm1001-37,
	0xd24f, // dwm1001-17,
	0xa847, // dwm1001-77,
	0xbb06, // dwm1001-95,
	0xb393, // dwm1001-1,
	0x03b5, // dwm1001-30,
	0xc3df, // dwm1001-33,
	0x69bb, // dwm1001-42,
	0x114d, // dwm1001-82,
	0x40c2, // dwm1001-86,
	0x6924, // dwm1001-41,
	0xc077, // dwm1001-38,
	0x13aa, // dwm1001-9,
	0x1af1, // dwm1001-65,
	0x8961, // dwm1001-81,
	0x5263, // dwm1001-5,
	0x03eb, // dwm1001-85,
	0x83b6, // dwm1001-29,
	0x34ea, // dwm1001-6,
	0xf237, // dwm1001-43,
	0x1bf6, // dwm1001-70,
	0xc2c8, // dwm1001-2,
	0xe91d, // dwm1001-74,
	0x83fd, // dwm1001-94,
	0xa4fa, // dwm1001-34,
	0xc729, // dwm1001-19,
	0x157f, // dwm1001-14,
	0xf6a8, // dwm1001-18,
	0x4739, // dwm1001-10,
	0xdcbc, // dwm1001-45,
	0xdab5, // dwm1001-63,
	0x2177, // dwm1001-21,
	0xbff4, // dwm1001-25,
	0x330f, // dwm1001-39,
	0x05ee, // dwm1001-89,
	0xb2a8, // dwm1001-26,
	0x7888, // dwm1001-62,
	0xf4cf, // dwm1001-73,
	0x8c51, // dwm1001-13,
	0xce09, // dwm1001-69,
	0x7c37  // dwm1001-93,
};

// maps ranging id to degree
uint16_t neighbor_graph_degree[NUM_NODES] = {
	28, // Node: dwm1001-35 (0)
	29, // Node: dwm1001-37 (1)
	25, // Node: dwm1001-17 (2)
	15, // Node: dwm1001-77 (3)
	12, // Node: dwm1001-95 (4)
	25, // Node: dwm1001-1 (5)
	28, // Node: dwm1001-30 (6)
	28, // Node: dwm1001-33 (7)
	29, // Node: dwm1001-42 (8)
	9,  // Node: dwm1001-82 (9)
	8,  // Node: dwm1001-86 (10)
	26, // Node: dwm1001-41 (11)
	29, // Node: dwm1001-38 (12)
	25, // Node: dwm1001-9 (13)
	12, // Node: dwm1001-65 (14)
	14, // Node: dwm1001-81 (15)
	25, // Node: dwm1001-5 (16)
	15, // Node: dwm1001-85 (17)
	30, // Node: dwm1001-29 (18)
	25, // Node: dwm1001-6 (19)
	29, // Node: dwm1001-43 (20)
	24, // Node: dwm1001-70 (21)
	25, // Node: dwm1001-2 (22)
	20, // Node: dwm1001-74 (23)
	9,  // Node: dwm1001-94 (24)
	28, // Node: dwm1001-34 (25)
	25, // Node: dwm1001-19 (26)
	26, // Node: dwm1001-14 (27)
	25, // Node: dwm1001-18 (28)
	25, // Node: dwm1001-10 (29)
	28, // Node: dwm1001-45 (30)
	14, // Node: dwm1001-63 (31)
	26, // Node: dwm1001-21 (32)
	28, // Node: dwm1001-25 (33)
	28, // Node: dwm1001-39 (34)
	14, // Node: dwm1001-89 (35)
	28, // Node: dwm1001-26 (36)
	19, // Node: dwm1001-62 (37)
	25, // Node: dwm1001-73 (38)
	26, // Node: dwm1001-13 (39)
	21, // Node: dwm1001-69 (40)
	12, // Node: dwm1001-93 (41)
};

uint16_t aloha_access_prob[NUM_NODES] = {
	400, 400, 400, 400, 400, 400, 400, 400, 400, 400, 400, 400, 400, 400, 400, 400, 400, 400,
	400, 400, 400, 400, 400, 400, 400, 400, 400, 400, 400, 400, 400, 400, 400, 400, 400, 400,
	400, 400, 400, 400, 400, 400,
};

int16_t node_factory_antenna_delay_offsets[NUM_NODES] = {
    0x00
};


float32_t node_distances[NUM_PAIRS] = {
    0x00
};

#endif
```
